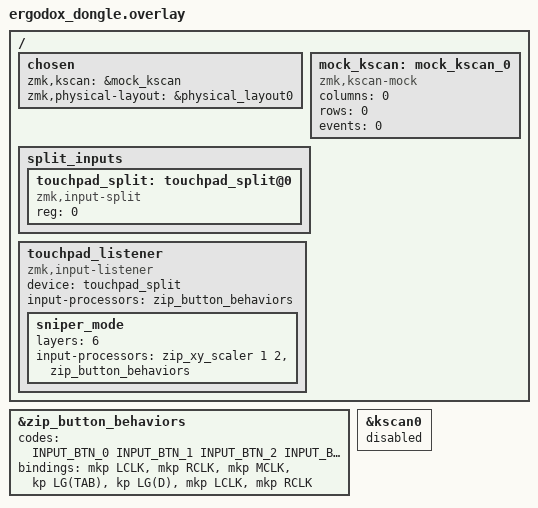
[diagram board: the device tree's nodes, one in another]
#include "ergodox.dtsi"
#include <input/processors.dtsi>
#include <dt-bindings/zmk/keys.h>
#include <dt-bindings/zmk/mouse.h>
#include <zephyr/dt-bindings/input/input-event-codes.h>

/ {
    chosen {
        zmk,kscan = &mock_kscan;
        zmk,physical-layout = &physical_layout0;
    };

    mock_kscan: mock_kscan_0 {
        compatible = "zmk,kscan-mock";
        columns = <0>;
        rows = <0>;
        events = <0>;
    };

    split_inputs {
        #address-cells = <1>;
        #size-cells = <0>;

        touchpad_split: touchpad_split@0 {
            compatible = "zmk,input-split";
            reg = <0>;
        };
    };

    touchpad_listener: touchpad_listener {
        compatible = "zmk,input-listener";
        device = <&touchpad_split>;
        input-processors = <&zip_button_behaviors>;

        sniper_mode {
            layers = <6>;
            input-processors = <&zip_xy_scaler 1 2>, <&zip_button_behaviors>;
        };
    };
};

&zip_button_behaviors {
    codes = <INPUT_BTN_0 INPUT_BTN_1 INPUT_BTN_2 INPUT_BTN_3 INPUT_BTN_4 INPUT_BTN_LEFT INPUT_BTN_RIGHT>;
    bindings = <&mkp LCLK &mkp RCLK &mkp MCLK &kp LG(TAB) &kp LG(D) &mkp LCLK &mkp RCLK>;
};

&kscan0 {
    status = "disabled";
};
